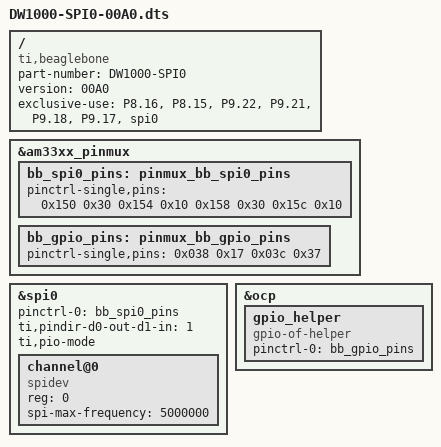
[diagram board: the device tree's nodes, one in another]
/*
* Copyright (C) 2016 Anh Luong <luong@eng.utah.edu>
*
* This program is free software; you can redistribute it and/or modify
* it under the terms of the GNU General Public License version 2 as
* published by the Free Software Foundation.
*/
/dts-v1/;
/plugin/;

/ {
	compatible = "ti,beaglebone", "ti,beaglebone-black", "ti,beaglebone-green";

	/* identification */
	part-number = "DW1000-SPI0";
	version = "00A0";

	/* state the resources this cape uses */
	exclusive-use =
		/* the pin header uses */
		"P8.16",	/* reset */
		"P8.15",	/* irq */
		"P9.22",	/* spi0_sclk */
		"P9.21",	/* spi0_d0 */
		"P9.18",	/* spi0_d1 */
		"P9.17",	/* spi0_cs0 */
		/* the hardware ip uses */
		"spi0";

	fragment@0 {
		target = <&am33xx_pinmux>;
		__overlay__ {
			/* default state has all gpios released and mode set to uart1 */
			bb_spi0_pins: pinmux_bb_spi0_pins {
				pinctrl-single,pins = <
					0x150 0x30	/* P9.22 sclk 		OUTPUT_PULLUP 	| MODE0 */
					0x154 0x10	/* P9.21 d0 		INPUT_PULLUP 	| MODE0 */
					0x158 0x30	/* P9.18 d1 		OUTPUT_PULLUP 	| MODE0 */
					0x15c 0x10	/* P9.17 cs0 		OUTPUT_PULLUP 	| MODE0 */
				>;
			};
			bb_gpio_pins: pinmux_bb_gpio_pins {
				pinctrl-single,pins = <
					0x038 0x17  /* P8.16 RESET  	O_PULLUP 				| MODE7-GPIO1[14] */
          			0x03c 0x37  /* P8.15 IRQ    	I_PULLUP 				| MODE7-GPIO1[15] */
				>;
			};
		};
	};
 
	fragment@1 {
		target = <&spi0>;
		__overlay__ {
			#address-cells = <1>;
			#size-cells = <0>;

			status = "okay";
			pinctrl-names = "default";
			pinctrl-0 = <&bb_spi0_pins>;
			ti,pindir-d0-out-d1-in = <1>;
			ti,pio-mode; /* disable dma when used as an overlay, dma gets stuck at 160 bits */
			
			channel@0 {
				#address-cells = <1>;
				#size-cells = <0>;

				compatible = "spidev";

				reg = <0>;
				spi-max-frequency = <5000000>;
			};
		};
	};

	fragment@2 {
		target = <&ocp>;
		__overlay__ {
			gpio_helper {
				compatible = "gpio-of-helper";
				status = "okay";
				pinctrl-names = "default";
				pinctrl-0 = <&bb_gpio_pins>;
			};
		};
	};
};
